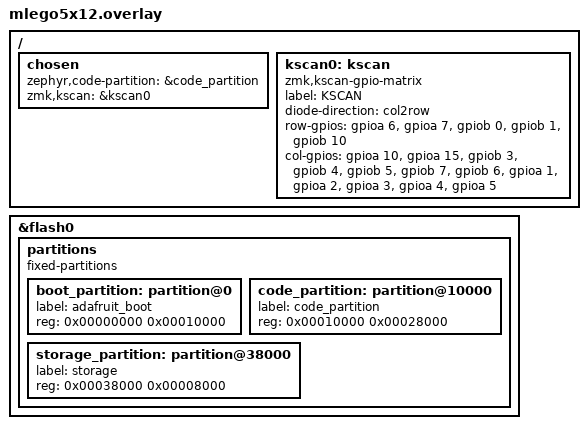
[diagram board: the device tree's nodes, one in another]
/*
 * Copyright (c) 2021 The ZMK Contributors
 *
 * SPDX-License-Identifier: MIT
 */

#include <dt-bindings/zmk/matrix_transform.h>

/ {
    chosen {
        zephyr,code-partition = &code_partition;
        zmk,kscan = &kscan0;
    };

    kscan0: kscan {
        compatible = "zmk,kscan-gpio-matrix";
        label = "KSCAN";
        diode-direction = "col2row";

        row-gpios
            = <&gpioa  6 (GPIO_ACTIVE_HIGH | GPIO_PULL_DOWN)>
            , <&gpioa  7 (GPIO_ACTIVE_HIGH | GPIO_PULL_DOWN)>
            , <&gpiob  0 (GPIO_ACTIVE_HIGH | GPIO_PULL_DOWN)>
            , <&gpiob  1 (GPIO_ACTIVE_HIGH | GPIO_PULL_DOWN)>
            , <&gpiob 10 (GPIO_ACTIVE_HIGH | GPIO_PULL_DOWN)>
            ;

        col-gpios
            = <&gpioa 10 GPIO_ACTIVE_HIGH>
            , <&gpioa 15 GPIO_ACTIVE_HIGH>
            , <&gpiob  3 GPIO_ACTIVE_HIGH>
            , <&gpiob  4 GPIO_ACTIVE_HIGH>
            , <&gpiob  5 GPIO_ACTIVE_HIGH>
            , <&gpiob  7 GPIO_ACTIVE_HIGH>
            , <&gpiob  6 GPIO_ACTIVE_HIGH>
            , <&gpioa  1 GPIO_ACTIVE_HIGH>
            , <&gpioa  2 GPIO_ACTIVE_HIGH>
            , <&gpioa  3 GPIO_ACTIVE_HIGH>
            , <&gpioa  4 GPIO_ACTIVE_HIGH>
            , <&gpioa  5 GPIO_ACTIVE_HIGH>
            ;
    };
}; 

&flash0 {
    partitions {
        compatible = "fixed-partitions";
        #address-cells = <1>;
        #size-cells = <1>;

        boot_partition: partition@0 {
            label = "adafruit_boot";
            reg = <0x00000000 0x00010000>;
        };

        code_partition: partition@10000 {
            label = "code_partition";
            reg = <0x00010000 0x00028000>;
        };

        /*
        * The final 32 KiB is reserved for the application.
        * Storage partition will be used by FCB/LittleFS/NVS
        * if enabled.
        */
        storage_partition: partition@38000 {
            label = "storage";
            reg = <0x00038000 0x00008000>;
        };
    };
};
